# cyw20829 register map
Vendor: Infineon Technologies; Series: CYW20829; File version: 1.0
CPU: CM33 r0p1, little endian, MPU, no FPU, VTOR, 3 interrupt priority bits
Registers are 32-bit, read-write, reset 0x0 unless marked. A register's access mark holds for its fields unless they carry their own. Offsets are from the block's base; [hi:lo] are bit positions; lines under a group give offsets from that group; {n}, {i} and the like mark numbered series; 'fields as' and 'values as' point back to an identical list; <NAME> marks a mode.

## SMIF0 — Serial Memory Interface
Base 0x40890000
0x00 CTL reset 0x503400 — Control
  [31] ENABLED — IP enable: '0': Disabled. All non-retention registers are reset to their default value when the IP is disabled. When the IP is disabled, the XIP accesses produce AHB-Lite bus errors and AXI error responses. '1': Enabled. Notes: - Before disabling or resetting the IP, SW should ensure that the IP is NOT busy (STATUS.BUSY is '0'), otherwise illegal interface transfers may occur. - After CTL.ENABLED is set to 1 it takes up to 20 clk_if cycles until the memory interface registers are realeased from reset.
    0=DISABLED (N/A); 1=ENABLED (N/A)
  [25] CLOCK_IF_SEL — Specifies the clock source for 'clk_if'. Must be 0 (clk_hf) before entering DeepSleep; can be returned to 1 (clk_pll) afterwards. '0': clk_hf is used to create clk_if '1': clk_pll is used to create clk_if
  [24] BLOCK — Specifies what happens for MMIO interface read accesses to an empty RX data FIFO or to a full TX format/data FIFO. This field is not used for test controller accesses.
    0=BUS_ERROR (0': Generate an AHB-Lite bus error. This option is useful when SW decides to use polling on STATUS.TR_BUSY to determine if a interface transfer is no longer busy (transfer is completed). This option adds SW complexity, but limits the number of AHB-Lite wait states (and limits ISR latency).); 1=WAIT_STATES (1': Introduce wait states. This setting potentially locks up the AHB-Lite infrastructure and may increase the CPU interrupt latency.This option is useful when SW performs TX/RX data FIFO accesses immediately after a command is setup using the TX format FIFO. This option has low SW complexity, but may result in a significant number of AHB-Lite wait states (and may increase ISR latency). This can be particularly true if ARB_MODE=1 and an MMIO access must wait a potentially long time behind a XIP access.)
  [23:22] SELECT_HOLD_DELAY — Specifies the duration between last 'spi_clk_out' edge to 'spi_select_out[]' becomes high/'1'): '0': 0 memory interface clock cycles + min. duration (see below). '1': 1 memory interface clock cycle + min. duration (see below). '2': 2 memory interface clock cycles + min. duration (see below). '3': 3 memory interface clock cycles + min. duration (see below). In addition to the number of cycles selected here there is a min. duration of: - 1/2 memory interface clock cycle (= 1 clk_if cycles) for SDR timing (CLOCK_IF_TX_SEL = 0) - 1/4 memory interface clock cycle (= 1/2 clk_if cycle) for DDR timing (CLOCK_IF_TX_SEL = 1)
  [21:20] SELECT_SETUP_DELAY — Specifies the duration between 'spi_select_out[]' becomes low/'0') to 1st 'spi_clk_out' edge: '0': 0 memory interface clock cycles + min. duration (see below). '1': 1 memory interface clock cycle + min. duration (see below). '2': 2 memory interface clock cycles + min. duration (see below). '3': 3 memory interface clock cycles + min. duration (see below). In addition to the number of cycles selected here there is a min. duration of: - 1 memory interface clock cycle (= 2 clk_if cycle) for SDR timing (CLOCK_IF_TX_SEL = 0) - 1/4 memory interface clock cycle (= 1/2 clk_if cycle) for DDR timing (CLOCK_IF_TX_SEL = 1)
  [18:16] DESELECT_DELAY — Specifies the minimum duration of SPI deselection ('spi_select_out[]' is high/'1') in between SPI transfers: '0': 1 memory interface clock cycle. '1': 2 memory interface clock cycles. '2': 3 memory interface clock cycles. '3': 4 memory interface clock cycles. '4': 5 memory interface clock cycles. '5': 6 memory interface clock cycles. '6': 7 memory interface clock cycles. '7': 8 memory interface clock cycles. During SPI deselection, 'spi_select_out[]' are '1'/inactive, 'spi_data_out[]' are '1' and 'spi_clk_out' is '0'/inactive.
  [14:12] CLOCK_IF_RX_SEL
  [11:10] INT_CLOCK_CAPTURE_CYCLE
  [9] INT_CLOCK_DL_ENABLED — Data Learning Enable for internal RX clock based on Data Learning Pattern. Only applies when CLOCK_IF_RX_SEL = [4..5] for selecting the internal clock based capture scheme and when DELAY_TAP_ENABLED = 1. Must be set to 0 otherwise. '0': Disabled. The delay line tap selections specified in registers INT_CLOCK_DELAY_TAP_SEL0/1 are not modified by HW. '1': Enabled. The delay linle tap selections specified in registers INT_CLOCK_DELAY_TAP_SEL0/1 are modified by HW based on the data learning pattern. From all capture clock delay line taps producing a match between the expected data learning pattern in register DLP and the captured data learning pattern from the memory device the middle one is selected.
  [8] DELAY_TAP_ENABLED — Delay Line Tap Enable. '0': Disabled. The delay line tap selections specified in registers DELAY_TAP_SEL or INT_CLOCK_DELAY_TAP_SEL0/1 are not used. The read data is directly captured by the RX data FIFO capture clock as specified by CLOCK_IF_RX_SEL and INT_CLOCK_CAPTURE_CYCLE. '1': Enabled. The delay line tap selections specified in registers DELAY_TAP_SEL or INT_CLOCK_DELAY_TAP_SEL0/1 are used. If the output / feedback clock based capture scheme (CLOCK_IF_RX_SEL = [0..3]) or the RWDS based capture scheme (CLOCK_IF_RX_SEL = [6..7]) is selected then the register DELAY_TAP_SEL is used to select the capture clock. If the internal clock based capture scheme (CLOCK_IF_RX_SEL = [4..5] and INT_CLOCK_CAPTURE_PRESENT = 1) is selected then the registers INT_CLOCK_DELAY_TAP_SEL0/1 are used to select the capture clock per data bit line (read data is captured by the capture logic and afterwards transferred to the RX data FIFO).
  [7:5] DELAY_LINE_SEL — Specifies the delay line used for RX data capturing with - output / feedback clock based capturing (when CLOCK_IF_RX_SEL = [0..3] and DELAY_TAP_ENABLED = 1) - internal clock based capturing (when CLOCK_IF_RX_SEL = [4..5], INT_CLOCK_CAPTURE_PRESENT = 1 and DELAY_TAP_ENABLED = 1) - RWDS based capturing (when CLOCK_IF_RX_SEL = [6..7])
  [4] CLOCK_IF_TX_SEL — Specifies device interface transmitter clock options. '0': SDR. Memory interface clock 'spihb_clk_out' is divided (by 2) interface clock 'clk_if', memory interface data signals are driven by divided (by 2) interface clock 'clk_if' with different phase than 'spihb_clk_out'. Results in driving memory interface data signals at falling 'spihb_clk_out' edge. '1': DDR. Memory interface clock 'spihb_clk_out' is divided (by 2) inverted interface clock 'clk_if_inv', memory interface data signals are driven with interface clock 'clk_if'. Results in driving memory interface data signals 90 degrees before rising and falling 'spihb_clk_out' edge.
  [0] XIP_MODE — Mode of operation. Note: this field should only be changed when the IP is disabled or when STATUS.BUSY is '0' and SW should not be executing from the XIP interface or MMIO interface.
    0=MMIO_MODE ('0': MMIO mode. Individual MMIO accesses to TX and RX FIFOs are used to generate a sequence of SPI transfers. This mode of operation allows for large flexibility in terms of the SPI transfers that can be generated.); 1=ARB_MODE (''1': Arbitration mode. Arbitrates XIP vs. MMIO accesses such that any ongoing, pending, or 'merged' transactions on XIP always take priority over any MMIO accesses to the device. However, if an MMIO access is in process it cannot be interrupted until it completes (as defined by sending the 'last command' via TX_CMD_MMIO_FIFO_WR). If MMIO accesses are not happening at all, though, then the XIP accesses endure no extra arbitration latency.)
0x04 STATUS ro reset not defined
  [31] BUSY — AHB Cache, AXI interface, cryptography, XIP, device interface, MPC (if present) initialization, or any other key logic busy in the IP: '0': not busy '1': busy When BUSY is '0', the IP can be safely disabled without: - the potential loss of transient write data. - the potential risk of aborting an inflight SPI device interface transfer. - disrupting MPC (if present) initialization When BUSY is '0', the mode of operation (ARB_MODE or MMIO_MODE) can be safely changed.
0x44 TX_CMD_FIFO_STATUS ro — Transmitter command FIFO status
  [3:0] USED4 — Number of entries that are used in the TX command FIFO. Legal range: [0, 8].
0x48 TX_CMD_MMIO_FIFO_STATUS ro — Transmitter command MMIO FIFO status
  [3:0] USED4 — Number of entries that are used in the TX command MMIO FIFO. Legal range: [0, 8].
0x50 TX_CMD_MMIO_FIFO_WR wo — Transmitter command MMIO FIFO write
  [26:0] DATA27
0x80 TX_DATA_MMIO_FIFO_CTL — Transmitter data MMIO FIFO control
  [2:0] TX_TRIGGER_LEVEL — Determines when the TX data MMIO FIFO 'tr_tx_req' trigger is activated: - Trigger is active when TX_DATA_MMIO FIFO_STATUS.USED <= TRIGGER_LEVEL.
0x84 TX_DATA_FIFO_STATUS ro — Transmitter data FIFO status
  [3:0] USED4 — Number of entries that are used in the TX data FIFO. Legal range: [0, 8].
0x88 TX_DATA_MMIO_FIFO_STATUS ro — Transmitter data MMIO FIFO status
  [3:0] USED4 — Number of entries that are used in the TX data MMIO FIFO. Legal range: [0, 8].
0x90 TX_DATA_MMIO_FIFO_WR1 wo — Transmitter data MMIO FIFO write
  [7:0] DATA0 — TX data (written to TX data MMIO FIFO).
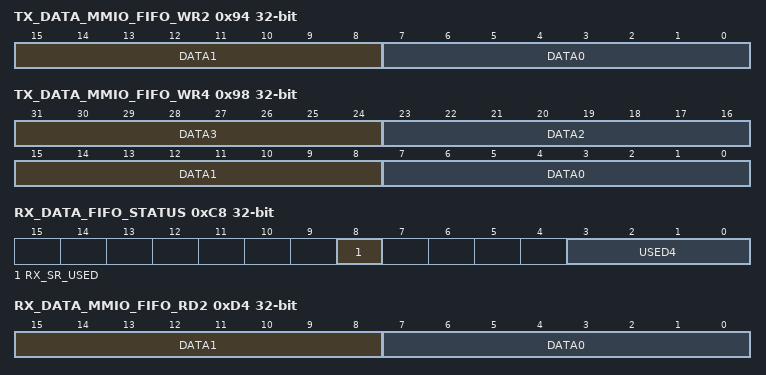
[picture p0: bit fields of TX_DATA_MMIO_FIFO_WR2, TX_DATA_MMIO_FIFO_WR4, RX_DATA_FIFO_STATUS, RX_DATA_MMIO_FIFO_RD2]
0x94 TX_DATA_MMIO_FIFO_WR2 wo — Transmitter data MMIO FIFO write
  [15:8] DATA1 — TX data (written to TX data MMIO FIFO, second byte).
  [7:0] DATA0 — TX data (written to TX data MMIO FIFO, first byte).
0x98 TX_DATA_MMIO_FIFO_WR4 wo — Transmitter data MMIO FIFO write
  [31:24] DATA3 — TX data (written to TX data MMIO FIFO, fourth byte).
  [23:16] DATA2 — TX data (written to TX data MMIO FIFO, third byte).
  [15:8] DATA1 — TX data (written to TX data MMIO FIFO, second byte).
  [7:0] DATA0 — TX data (written to TX data MMIO FIFO, first byte).
0x9C TX_DATA_MMIO_FIFO_WR1ODD wo — Transmitter data MMIO FIFO write
  [7:0] DATA0 — TX data (written to TX data MMIO FIFO).
0xC0 RX_DATA_MMIO_FIFO_CTL — Receiver data MMIO FIFO control
  [2:0] RX_TRIGGER_LEVEL — Determines when RX data FIFO 'tr_rx_req' trigger is activated: - Trigger is active when RX_DATA_MMIO_FIFO_STATUS.USED > TRIGGER_LEVEL.
0xC4 RX_DATA_MMIO_FIFO_STATUS ro — Receiver data MMIO FIFO status
  [3:0] USED4 — Number of entries that are used in the RX data MMIO FIFO. Legal range: [0, 8].
0xC8 RX_DATA_FIFO_STATUS ro — Receiver data FIFO status
  [8] RX_SR_USED — Data available in RX Shift Register, i.e. completely read from RX data FIFO.
  [3:0] USED4 — Number of entries that are used in the RX data FIFO. Legal range: [0, 8].
0xD0 RX_DATA_MMIO_FIFO_RD1 ro — Receiver data MMIO FIFO read
  [7:0] DATA0 — RX data (read from RX data FIFO).
0xD4 RX_DATA_MMIO_FIFO_RD2 ro — Receiver data MMIO FIFO read
  [15:8] DATA1 — RX data (read from RX data FIFO, second byte).
  [7:0] DATA0 — RX data (read from RX data FIFO, first byte).
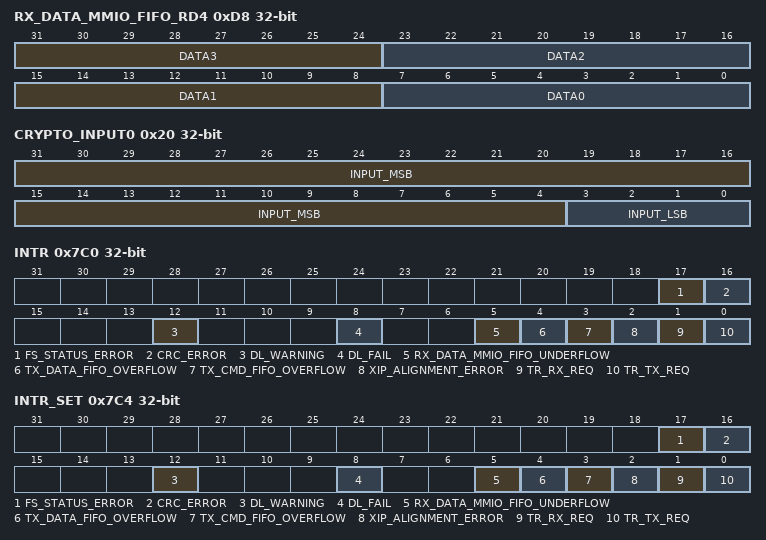
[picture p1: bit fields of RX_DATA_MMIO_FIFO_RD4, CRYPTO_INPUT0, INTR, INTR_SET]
0xD8 RX_DATA_MMIO_FIFO_RD4 ro — Receiver data MMIO FIFO read
  [31:24] DATA3 — RX data (read from RX data FIFO, fourth byte).
  [23:16] DATA2 — RX data (read from RX data FIFO, third byte).
  [15:8] DATA1 — RX data (read from RX data FIFO, second byte).
  [7:0] DATA0 — RX data (read from RX data FIFO, first byte).
0xE0 RX_DATA_MMIO_FIFO_RD1_SILENT ro — Receiver data MMIO FIFO silent read
  [7:0] DATA0 — RX data (read from RX data FIFO).
0x200 SMIF_CRYPTO group — Cryptography registers (one set for each key)
  0x00 CRYPTO_CMD — Cryptography command
    [0] START — SW sets this field to '1' to start an AES-128 forward block cipher operation (on CRYPTO_INPUT0-3). HW sets this field to '0' to indicate that the operation has completed. Once completed, the result of the operation can be read from CRYPTO_OUTPUT0, ..., CRYPTO_OUTPUT3. The operation takes roughly 13 clk_mem clock cycles. This register is only applicable for MMIO accesses and only in MMIO_MODE. XIP accesses are encrypted on-the-fly in ARB_MODE and thus do not use this register. Because XIP has exclusive access to the crypto engine in ARB_MODE, MMIO encryption is not available in that mode. As such if encryption is needed for MMIO accesses in ARB_MODE that encryption must be done by other means (i.e., chip level crypto).
  0x04 CRYPTO_ADDR — Cryptography base address
    [31:8] ADDR — Only applies to XIP accesses. Specifies the base address of the memory region that will have cryptography applied on XIP accesses with a unique key. If this region overlaps with another key's region, the lower numbered key is used (i.e., crypto key 0 has the highest priority). If the region is 2^m Bytes, ADDR MUST be a multiple of 2^m. The most significant bit fields are constants and set based on the SMIF_XIP_ADDR parameter. The most significant bits are identified on the SMIF_XIP_MASK parameter. E.g., if SMIF_XIP_MASK is 0xff00:0000 (16 MB XIP memory region), ADDR[31:24] = SMIF_XIP_ADDR[31:24]. Note that in order for cryptogrpahy to be applied the DEVICE.CTL.CRYPTO_EN must be set to 1 as well for any devices that share this region.
  0x08 CRYPTO_MASK — Cryptography mask
    [31:8] MASK — Only applies to XIP accesses. Specifies the size of the memory region whose base address is determined by CRYPTO_ADDR. All '1' bits are used to compare the incoming transfer request address A[31:0] with the address as specified in CRYPTO_ADDR.ADDR: Address A is in the cryptography region when (A[31:8] & MASK[31:8]) == CRYPTO_ADDR.ADDR[31:8]. The most significant bit fields are constants and set to'1'. The most significant bits are identified on the SMIF_XIP_MASK parameter. E.g., if SMIF_XIP_MASK is 0xff00:0000 (16 MB XIP memory region), MASK[31:24] = 0xff.
  0x0C CRYPTO_SUBREGION — Cryptography subregion disable
    [7:0] SUBREGION_DISABLE — Only applies to XIP accesses. The cryptography region for this key as determined by CRYPTO_ADDR and CRYPTO_MASK is further divided into 8 equal subregions. e.g., if a 1 MB region is specified then the 8 subregions will be 128 KB. If SUBREGION_DISABLE=0 then cryptography will be performed on that subregion (assuming any associated DEVICE.CTL.CRYPTO_EN=1). Otherwise if SUBREGION_DISABLE=1 then cryptography is not applied. Note that setting all SUBREGION_DISABLE bits to 1 will effectively disable this key. The encryption decision and the associated key are locked in at the beginning of a memory access and will apply until the end of such atomic accesses. Therefore, it is the user's responsibility to ensure memory accesses do not span across (sub)regions that have different keys and/or cypto enabled/disabled differently across such (sub)regions.
  0x20 CRYPTO_INPUT0 reset not defined — Cryptography input 0
    [31:4] INPUT_MSB — Plaintext PT[31:4] = CRYPTO_INPUT0.INPUT_MSB.
    [3:0] INPUT_LSB — Plaintext PT[3:0] = CRYPTO_INPUT0.INPUT_LSB.
  {0x20+4j} CRYPTO_INPUT{j} reset not defined (j=1..3) — Cryptography input {j}
    [31:0] INPUT — Plaintext PT[{32j+31}:{32j}] = CRYPTO_INPUT{j}.INPUT[31:0].
  {0x40+4j} CRYPTO_KEY{j} wo reset not defined (j=0..3) — Cryptography key {j}
    [31:0] KEY — Four Bytes of the key KEY[{32j+31}:{32j}] = CRYPTO_KEY{j}.KEY[31:0].
  {0x60+4j} CRYPTO_OUTPUT{j} reset not defined (j=0..3) — Cryptography output {j}
    [31:0] OUTPUT — Four Bytes of the ciphertext CT[{32j+31}:{32j}] = CRYPTO_OUTPUT{j}.OUTPUT[31:0].
0x7C0 INTR — Interrupt register
  [17] FS_STATUS_ERROR — Functional Safety Status Error. A read transfer Functional Safety Status check failed (see definition in DEVICE_ver2.RD_CRC_CTL.STATUS_CHECK_MASK and DEVICE_ver2.RD_CRC_CTL.STATUS_CHECK_MASK_POL).
  [16] CRC_ERROR — CRC Error. A read transfer data CRC check failed.
  [12] DL_WARNING — Data Learning Warning (for at least one input data line less then DLP.DL_WARNING_LEVEL delay line taps resulted in a correct DLP capturing when CTL.INT_CLOCK_DL_ENABLED = 1). This interrupt will be suppressed, though, if DL_FAIL also occurs during the same DLP evaluation cycle.
  [8] DL_FAIL — Data Learning Failed (no DLP match found on at least one of the input data lines when CTL.INT_CLOCK_DL_ENABLED = 1).
  [5] RX_DATA_MMIO_FIFO_UNDERFLOW — Activated on an AHB-Lite read transfer from the RX data MMIO FIFO (RX_DATA_MMIO_FIFO_RD1, RX_DATA_MMIO_FIFO_RD2, RX_DATA_MMIO_FIFO_RD4) with not enough entries available. Only activated for NON test bus controller transfers.
  [4] TX_DATA_FIFO_OVERFLOW — Activated on an AHB-Lite write transfer to the TX data MMIO FIFO (TX_DATA_MMIO_FIFO_WR1, TX_DATA_MMIO_FIFO_WR2, TX_DATA_MMIO_FIFO_WR4, TX_DATA_MMIO_FIFO_WR1ODD) with not enough free entries available.
  [3] TX_CMD_FIFO_OVERFLOW — Activated on an AHB-Lite write transfer to the TX command MMIO FIFO (TX_CMD_MMIO_FIFO_WR) with not enough free entries available.
  [2] XIP_ALIGNMENT_ERROR — Activated on a XIP access, when: - a write transfer is requested and - Dual-Quad SPI mode (selected device's ADDR_CTL.DIV2 is '1') is selected or - Octal SPI DDR mode (selected device's DATA_CTL.DDR_MODE = '1' and DATA_CTL.WIDTH = '3') or Hyperbus mode (selected device's ADDR_CTL.SIZE3 = '7') is selected without memory write byte masking (selected device's WR_DUMMY_CTL.RWDS_EN = '0') and - the AHB-Lite / AXI bus transfer address is not a multiple of '2' or - the requested AHB-Lite / AXI bus transfer size is NOT a multiple of '2'. Additionally, it is activated on a XIP access when the selected memory device does not support write byte masking (WR_DUMMY_CTL.RWDS_EN=0) and an AXI transfer occurs with not all of the AXI write strobes ('wstrb') enabled according to the transfer size ('assize'). Note: In dual-quad SPI mode (ADDR_CTL.DIV is '1'), each memory device contributes a 4-bit nibble for read data or write data. Write accesses are only possible if the request address is a multiple of 2 and the number of requested Bytes is a multiple of 2. Octal SPI DDR mode or Hyperbus mode are 16-bit word based protocols, writing single bytes is only possible when write byte masking is supported (via RWDS). Read accesses are always possible by extending the transfer size and / or aligning the address as needed and discarding the non-relevant byte(s).
  [1] TR_RX_REQ — Activated when a RX data MMIO FIFO trigger 'tr_rx_req' is activated.
  [0] TR_TX_REQ — Activated when a TX data MMIO FIFO trigger 'tr_tx_req' is activated.
0x7C4 INTR_SET — Interrupt set register
  [17] FS_STATUS_ERROR — Write with '1' to set corresponding bit in interrupt request register.
  [16] CRC_ERROR — Write with '1' to set corresponding bit in interrupt request register.
  [12] DL_WARNING — Write with '1' to set corresponding bit in interrupt request register.
  [8] DL_FAIL — Write with '1' to set corresponding bit in interrupt request register.
  [5] RX_DATA_MMIO_FIFO_UNDERFLOW — Write with '1' to set corresponding bit in interrupt request register.
  [4] TX_DATA_FIFO_OVERFLOW — Write with '1' to set corresponding bit in interrupt request register.
  [3] TX_CMD_FIFO_OVERFLOW — Write with '1' to set corresponding bit in interrupt request register.
  [2] XIP_ALIGNMENT_ERROR — Write with '1' to set corresponding bit in interrupt request register.
  [1] TR_RX_REQ — Write with '1' to set corresponding bit in interrupt request register.
  [0] TR_TX_REQ — Write with '1' to set corresponding bit in interrupt request register.
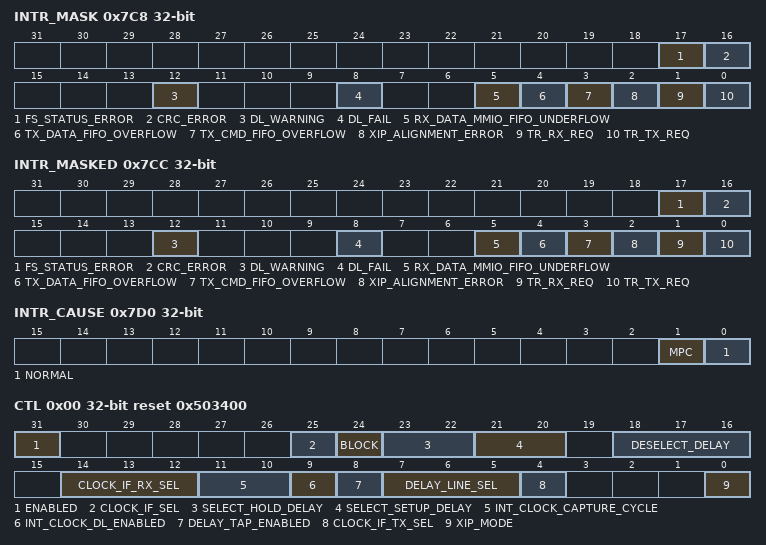
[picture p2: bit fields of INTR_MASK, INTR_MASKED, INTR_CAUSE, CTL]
0x7C8 INTR_MASK — Interrupt mask register
  [17] FS_STATUS_ERROR — Mask bit for corresponding bit in interrupt request register.
  [16] CRC_ERROR — Mask bit for corresponding bit in interrupt request register.
  [12] DL_WARNING — Mask bit for corresponding bit in interrupt request register.
  [8] DL_FAIL — Mask bit for corresponding bit in interrupt request register.
  [5] RX_DATA_MMIO_FIFO_UNDERFLOW — Mask bit for corresponding bit in interrupt request register.
  [4] TX_DATA_FIFO_OVERFLOW — Mask bit for corresponding bit in interrupt request register.
  [3] TX_CMD_FIFO_OVERFLOW — Mask bit for corresponding bit in interrupt request register.
  [2] XIP_ALIGNMENT_ERROR — Mask bit for corresponding bit in interrupt request register.
  [1] TR_RX_REQ — Mask bit for corresponding bit in interrupt request register.
  [0] TR_TX_REQ — Mask bit for corresponding bit in interrupt request register.
0x7CC INTR_MASKED ro — Interrupt masked register
  [17] FS_STATUS_ERROR — Logical and of corresponding request and mask bits.
  [16] CRC_ERROR — Logical and of corresponding request and mask bits.
  [12] DL_WARNING — Logical and of corresponding request and mask bits.
  [8] DL_FAIL — Logical and of corresponding request and mask bits.
  [5] RX_DATA_MMIO_FIFO_UNDERFLOW — Logical and of corresponding request and mask bits.
  [4] TX_DATA_FIFO_OVERFLOW — Logical and of corresponding request and mask bits.
  [3] TX_CMD_FIFO_OVERFLOW — Logical and of corresponding request and mask bits.
  [2] XIP_ALIGNMENT_ERROR — Logical and of corresponding request and mask bits.
  [1] TR_RX_REQ — Logical and of corresponding request and mask bits.
  [0] TR_TX_REQ — Logical and of corresponding request and mask bits.
0x7D0 INTR_CAUSE ro — Distinguishes normal vs. MPC interrupt
  [1] MPC — Reflects the state of interrupt_mpc (which is the OR of the elements in the MPC'S INTR_MASKED)
  [0] NORMAL — Reflects the state of interrupt_normal (which is the OR of the elements in the normal INTR_MASKED)
{0x800+0x80*i} DEVICE[{i}] (i=0..1) group — Device (only used for XIP acceses)
  0x00 CTL — Control
    [31] ENABLED — Device enable: '0': Disabled. '1': Enabled.
    [30] TOTAL_TIMEOUT_EN — Total transfer timeout enable. '0': Disabled. There is no limit for the total transfer time. The continuous transfer merge timeout for limiting the idle time of the memory interface still applies. '1': Enabled. The maximum total transfer time is limited by field TOTAL_TIMEOUT.
    [29:16] TOTAL_TIMEOUT — Total transfer timeout in clk_mem cycles. The counting of the total timout period is done in the XIP block using clk_mem cycles. It starts when the first command of a new (not merged) transaction is transferred to the TX command FIFO causing the interface logic to select the memory. After this period the memory device is deselected. This feature is needed for RAM devices requiring refresh cycles. The value needs to be derived from the RAMs maximum transaction length time (tCMS) minus the time of transferring 2x16byte data block (data granularity of the XIP ports is 16byte, 1 16byte block transfer outstanding, another available for merging). If the result in negative, MERGE_EN must be set to '0'. Example: RAM device tCMS = 4us, interface clock frequency = 100MHz: total transfer timeout is 4us - 2x16x10ns = 3680ns. With clk_mem frequency of 200MHz the TOTAL_TIMEOUT value is 3680/5 = 736. Note: In the unlikely case that the total transfer timeout is used (usually for RAM devices) while the page boundary crossing latency generation is enabled via RD_BOUND_CTL.PRESENT (usually for FLASH devices) the additional time needs to taken into account.
    [15] MERGE_EN — Continous transfer merge enable: '0': Disabled. No merging of transfers is done. Longest possible memory transfer is 16 Byte. '1': Enabled. Merging of continous transfers is done. This skips the overhead (command, address, mode, dummy cycles) for a continuous (linear sequential) transfer.
    [14:12] MERGE_TIMEOUT — Continuous transfer merge timeout in clk_mem cycles. This limits the standby time of the memory interface, i.e. the time the memory device is selected but no data is transferred. The counting of the merge timeout period is done in the XIP block using clk_mem cycles. It starts when the last TX or RX byte is transferred to or from the data FIFOs. After this period the memory device is deselected. A later transfer, even from a continuous address, starts with the overhead phases (command, address, mode, dummy cycles).
      0=_1_cycle (Timeout after 1 clk_mem cycle. That means transfers will only be merged if the continuous transfer request is already available when the previous transfer is finished.); 1=_16_cycles (Timeout after 2^4 = 16 clk_mem cycles. At a clk_mem frequency of 200MHz this means 80ns.); 2=_256_cycles (Timeout after 2^8 = 256 clk_mem cycles. At a clk_mem frequency of 200MHz this means ~1.3us.); 3=_4096_cycles (Timeout after 2^12 = 4096 clk_mem cycles. At a clk_mem frequency of 200MHz this means ~20us.); 4=_65536_cycles (Timeout after 2^16 = 65536 clk_mem cycles. At a clk_mem frequency of 200MHz this means ~330us.); 5=RSVD5 (N/A); 6=RSVD6 (N/A); 7=RSVD7 (N/A)
    [9:8] DATA_SEL — Specifies the connection of the IP's data lines (spi_data[0], ..., spi_data[7]) to the device's data lines (SI/IO0, SO/IO1, IO2, IO3, IO4, IO5, IO6, IO7): '0': spi_data[0] = IO0, spi_data[1] = IO1, ..., spi_data[7] = IO7. This value is allowed for single, dual, quad, dual quad and octal SPI modes. This value must be used for the first device in dual quad SPI mode. This value must be used for octal SPI mode. '1': spi_data[2] = IO0, spi_data[3] = IO1. This value is only allowed for single and dual SPI modes. '2': spi_data[4] = IO0, spi_data[5] = IO1, ..., spi_data[7] = IO3. This value is only allowed for single, dual, quad and dual quad SPI modes. In dual quad SPI mode, this value must be used for the second device. '3': spi_data[6] = IO0, spi_data[7] = IO1. This value is only allowed for single and dual SPI modes.
    [4] CRYPTO_EN — Cryptography on read/write accesses: '0': disabled. '1': enabled.
    [0] WR_EN — Write enable: '0': write transfers are not allowed to this device. An attempt to write to this device results in an AHB-Lite bus error. '1': write transfers are allowed to this device.
  0x08 ADDR reset not defined — Device region base address
    [31:8] ADDR — Specifies the base address of the device region. If the device region is 2^m Bytes, ADDR MUST be a multiple of 2^m. In dual quad SPI data transfer, the two devices should have the same ADDR and MASK register settings. The device control information (ADDR_CTL, RD_CMD_CTL, etc.) are provided by the MMIO control registers of the device with the lowest index. The most significant bit fields are constants and set based on the SMIF_XIP_ADDR parameter. The most significant bits are identified on the SMIF_XIP_MASK parameter. E.g., if SMIF_XIP_MASK is 0xff00:0000 (16 MB XIP memory region), ADDR[31:24] = SMIF_XIP_ADDR[31:24].
  0x0C MASK reset not defined — Device region mask
    [31:8] MASK — Specifies the size of the device region. All '1' bits are used to compare the incoming transfer request address A[31:0] with the address as specified in ADDR.ADDR: Address A is in the device when (A[31:8] & MASK[31:8]) == ADDR.ADDR[31:8]. The most significant bit fields are constants and set to'1'. The most significant bits are identified on the SMIF_XIP_MASK parameter. E.g., if SMIF_XIP_MASK is 0xff00:0000 (16 MB XIP memory region), MASK[31:24] = 0xff. Note: a transfer request that is not in any device region results in an AHB-Lite bus error.
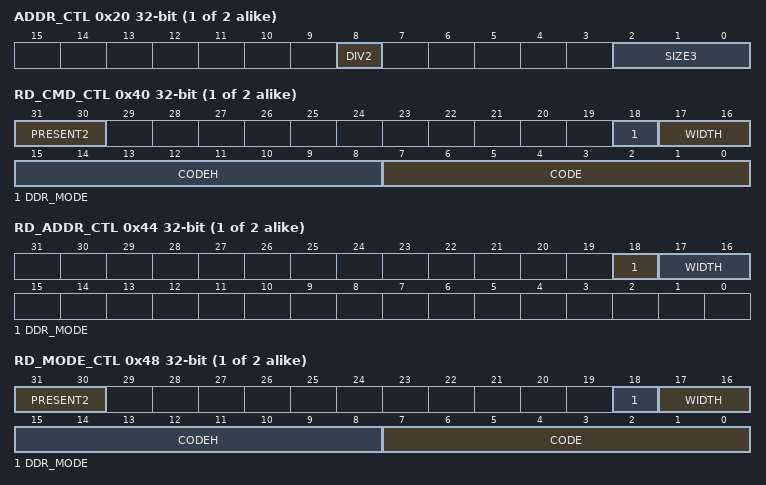
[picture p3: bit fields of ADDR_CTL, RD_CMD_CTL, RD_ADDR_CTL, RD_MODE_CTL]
  0x20 ADDR_CTL — Address control
    [8] DIV2 — Specifies if the AHB-Lite bus transfer address is divided by 2 or not: '0': No divide by 2. '1': Divide by 2. This functionality is used for read and write operation in XIP, dual quad SPI mode; i.e. this DIV2 must be set to '1' in dual quad SPI mode. If DIV2 is set to '1', the memory does not support write masking (WR_DUMMY_CTL.RWDS_EN = '0'), and in this configuration a write transfer is requested and the write transfer request address is NOT a multiple of 2 or the requested number of Bytes to be written is not a multiple of 2, the XIP_ALIGNMENT_ERROR interrupt cause is activated.
    [2:0] SIZE3
  0x2C DELAY_TAP_SEL reset 0x1 — RX Clock Delay Tap Select Register
    [7:0] SEL — Delay line tap selection in output / feedback clock based capture scheme (CLOCK_IF_RX_SEL = [0..3]) and RWDS capture scheme (CLOCK_IF_RX_SEL = [6..7]). This is used to shift the strobe signal into the data eye. Any 2 devices connected in a dual quad SPI arrangement must set this register equivalently. Note: DELAY_TAP_SEL must not be changed while STATUS.BUSY=1.
  0x30 RD_STATUS ro — Read status
    [7:0] FS_STATUS — Provides the Functional Safety Status Register of the memory received with the last read transfer.
  0x40 RD_CMD_CTL — Read command control
    [31:30] PRESENT2 — Presence of command field: '0': not present '1': present (1 Byte) '2': present (2 Byte for OPI) Note: For octal data transfer with DDR mode (WIDTH='3' and DDR_MODE='1') either the HB protocol needs to be selected (by ADDR_CTL.SIZE3='7') or this field needs to be set to PRESENT2='2'.
    [18] DDR_MODE — Mode of transfer rate: '0': SDR mode '1': DDR mode
    [17:16] WIDTH — Width of data transfer: '0': 1 bit/cycle (single data transfer). '1': 2 bits/cycle (dual data transfer). '2': 4 bits/cycle (quad data transfer). '3': 8 bits/cycle (octal data transfer).
    [15:8] CODEH — Command high byte code. This field specifies the most significant command byte, sent before the least significant command byte (CODE). It is only used when PRESENT2 = '2'.
    [7:0] CODE — Command byte code.
  0x44 RD_ADDR_CTL — Read address control
    [18] DDR_MODE — Mode of transfer rate.
    [17:16] WIDTH — Width of transfer.
  0x48 RD_MODE_CTL — Read mode control
    [31:30] PRESENT2 — Presence of mode field: '0': not present '1': present (1 Byte) '2': present (2 Byte for OPI) Note: For octal data transfer with DDR mode (WIDTH='3' and DDR_MODE='1') this field needs to be set to PRESENT2='2' to generate a mode field (or to PRESENT2='0').
    [18] DDR_MODE — Mode of transfer rate.
    [17:16] WIDTH — Width of transfer.
    [15:8] CODEH — Mode high byte code. This field specifies the most significant mode byte, sent before the least significant mode byte (CODE). It is only used when PRESENT2 = '2'.
    [7:0] CODE — Mode byte code. Note: If a mode field is present (PRESENT='1') for octal data transfer with DDR mode (WIDTH='3' and DDR_MODE='1') the CODE is sent twice.
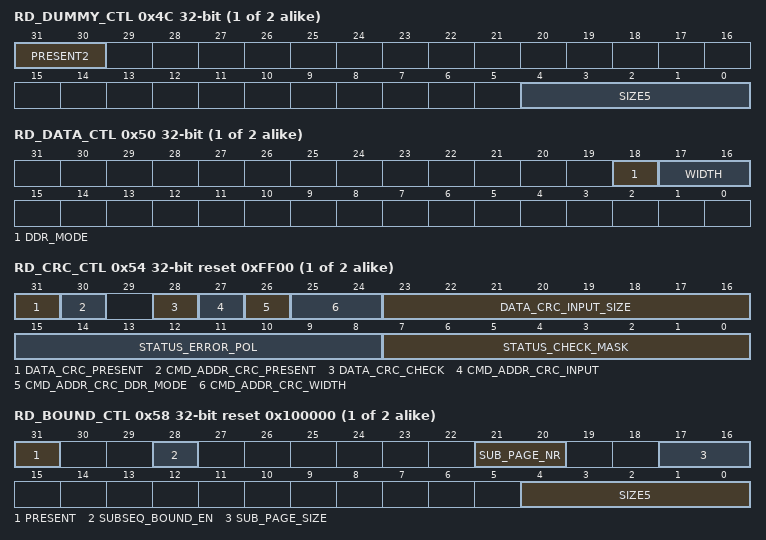
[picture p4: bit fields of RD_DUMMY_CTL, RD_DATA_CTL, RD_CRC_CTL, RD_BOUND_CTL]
  0x4C RD_DUMMY_CTL — Read dummy control
    [31:30] PRESENT2 — Presence of dummy cycles: '0': not present '1': present '2': present - Dummy cycles are doubled when RWDS refresh indicator is high during CA cycle. (HyperRAM variable latency mode) Notes: - If CLOCK_IF_TX_SEL = '0' for transmitting command, address and mode fields in SDR mode (driving data between falling edges of spihb_clk_out) and the memory is driving read data in DDR mode (based on memory type and transmitted command), then there must be at least 1 latency / dummy cycle specified (RD_DUMMY_CTL.PRESENT2 > 0') to prevent controller and memory driving data signals at the same time. The same is true for the theoretical (practically irrelevant case) of transmitting at least one of the command, address and mode fields in DDR mode but receiving data from the memory in SDR mode. - When using the RWDS / DQS based capturing scheme (CTL.CLK_IF_RX_SEL=[6,7]), then there is a minimum number of latency / dummy cycles required (RD_DUMMY_CTL.PRESENT2 > 0). For the Hyperbus protocol (DDR_CTL.SIZE3=7) at least 1 latency / dummy cycle has to be specified, for SPI with DQS capturing at least 2 latency / dummy cycles need to be selected (RD_DUMMY_CTL.SIZE5 > 0, exception see following note). - In case of falling edge RWDS / DQS capturing (CTL.CLOCK_IF_RX_SEL = '6') and SDR mode, SW should reduce the number of dummy cycles by 1 compared to the latency cycles required by the memory device. -DDR read commands need at least one dummy cycle -For Hyperbus, set RD DUMMY_CTL.SIZE5=initial latency cycles-2
    [4:0] SIZE5 — Number of dummy cycles (minus 1): '0': 1 cycles ... '31': 32 cycles. Note: this field specifies dummy cycles, not dummy Bytes!
  0x50 RD_DATA_CTL — Read data control
    fields as DEVICE[0].RD_ADDR_CTL
  0x54 RD_CRC_CTL reset 0xFF00 — Read Bus CRC control
    [31] DATA_CRC_PRESENT — Presence of data CRC field: '0': not present '1': present Note: Width and data transfer mode (SDR or DDR) of read data CRC fields are the same as for the associated read data fields, i.e. are specified by RD_DATA_CTL.WIDTH and RD_DATA_CTL.DDR_MODE.
    [30] CMD_ADDR_CRC_PRESENT — Presence of command / address CRC field: '0': not present '1': present Note: For octal data transfer with DDR mode (RD_CRC_CTL.WIDTH='3' and RD_CRC_CTL.DDR_MODE='1') the command / address CRC byte is sent twice, otherwise the command / address CRC byte is only sent once.
    [28] DATA_CRC_CHECK
    [27] CMD_ADDR_CRC_INPUT — Specifies which fields are included in the command / address CRC generation. '0': The command / address CRC field is generated over the address and (if present) mode fields only. '1': The command / address CRC field is generated over the command, address and (if present) mode fields.
    [26] CMD_ADDR_CRC_DDR_MODE — Mode of transfer rate of command / address CRC field.
    [25:24] CMD_ADDR_CRC_WIDTH — Width of command / address CRC field.
    [23:16] DATA_CRC_INPUT_SIZE — Number of input data bytes for CRC generation (minus 1), i.e. number of data bytes over which the data CRC field is generated (minus 1): '0': 1 byte ... '255': 256 bytes. Note: For octal data transfer with DDR mode (RD_DATA_CTL.WIDTH='3' and RD_DATA_CTL.DDR_MODE='1') the number of bytes for CRC generation must be even (i.e. DATA_CRC_INPUT_SIZE must be odd).
    [15:8] STATUS_ERROR_POL — Specifies the polarity of the Functional Safety Status field bits. There is 1 polarity bit for each Functional Safety Status bit. '0': The associated Functional Safety Status bit is active-low. '1': The associated Functional Safety Status bit is active-high.
    [7:0] STATUS_CHECK_MASK — Specifies which of the Functional Safety Status field bits are checked. There is 1 mask bit for each Functional Safety Status bit. '0': The associated Functional Safety Status bit is not checked. '1': The associated Functional Safety Status bit is checked. If the received Funciontal Safety Status bit = Functional Safety Status Error Polarity (STATUS_ERROR_POLARITY), then a Functional Safety Status error interrupt and a XIP bus error response is generated.
  0x58 RD_BOUND_CTL reset 0x100000 — Read boundary control
    [31] PRESENT — Presence of first page boundary latency cycles: '0': not present '1': present
    [28] SUBSEQ_BOUND_EN — Enable subsequent page boundary latency cycles. '0': Disabled. The page crossing latency cycles are only generated when crossing the first page boundary (i.e. the first time when the SUB_PAGE_NRth sub page boundary is crossed, e.g. with 2 sub pages per page when the 2nd sub page boundary is crossed). '1': Enabled. The page crossing latency cycles are generated when crossing the first and subsequent page boundaries (i.e. every time when a SUB_PAGE_NRth sub page boundary is crossed, e.g. with 2 sub pages per page when the 2nd, 4th, 6th, ... sub page boundary is crossed). Note: This only applies when the number of base latency cycles (SIZE5+1) is greater than the size of a page (base_latency > page_size). Must be set to 0 otherwise.
    [21:20] SUB_PAGE_NR — Specifies the number of sub pages per page. '0': 1 sub pages per page, i.e. page_size = sub_page_size '1': 2 sub pages per page, i.e. page_size = 2 x sub_page_size '2': 4 sub pages per page, i.e. page_size = 4 x sub_page_size '3': 8 sub pages per page, i.e. page_size = 8 x sub_page_size
    [17:16] SUB_PAGE_SIZE — Specifies the size of a memory sub page 'sub_page_size'. '0': sub_page_size = 8 words = 16 bytes (default). '1': sub_page_size = 16 words = 32 bytes. '2': sub_page_size = 32 words = 64 bytes. '3': sub_page_size = 64 words = 128 bytes.
    [4:0] SIZE5 — Number of base latency cycles (minus 1) used for calculating the number of fist page boundary crossing latency cycles: '0': base_latency = 1 cycles ... '31': base_latency = 32 cycles. The actual latency cycles when crossing the first page boundary depend on the start address of the transaction and is calculated as follows: if ((page_size - base_latency) < Start_Addr & (sub_page_size - 1)) { ((Start_Addr & (sub_page_size - 1)) - page_size + base_latency) } else { 0 }
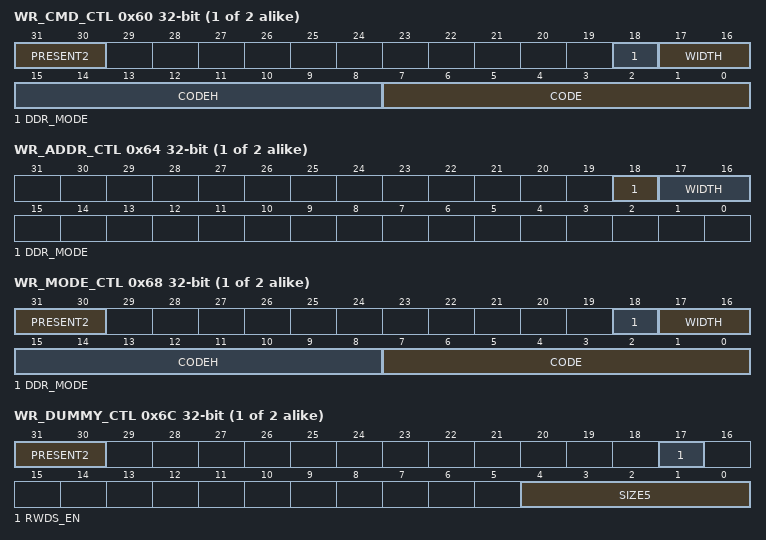
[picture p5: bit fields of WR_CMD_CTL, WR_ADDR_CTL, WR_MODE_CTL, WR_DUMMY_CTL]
  0x60 WR_CMD_CTL — Write command control
    [31:30] PRESENT2 — Presence of command field: '0': not present '1': present (1 Byte) '2': present (2 Byte for OPI) Note: For octal data transfer with DDR mode (WIDTH='3' and DDR_MODE='1') either the HB protocol needs to be selected (by ADDR_CTL.SIZE3='7') or this field needs to be set to PRESENT2='2'.
    [18] DDR_MODE — Mode of transfer rate.
    [17:16] WIDTH — Width of transfer.
    [15:8] CODEH — Command high byte code. This field specifies the most significant command byte, sent before the least significant command byte (CODE). It is only used when PRESENT2 = '2'.
    [7:0] CODE — Command byte code.
  0x64 WR_ADDR_CTL — Write address control
    fields as DEVICE[0].RD_ADDR_CTL
  0x68 WR_MODE_CTL — Write mode control
    [31:30] PRESENT2 — Presence of mode field: '0': not present '1': present (1 Byte) '2': present (2 Byte for OPI) Note: For octal data transfer with DDR mode (WIDTH='3' and DDR_MODE='1') this field needs to be set to PRESENT2='2' to generate a mode field (or to PRESENT2='0').
    [18] DDR_MODE — Mode of transfer rate.
    [17:16] WIDTH — Width of transfer.
    [15:8] CODEH — Mode high byte code. This field specifies the most significant mode byte, sent before the least significant mode byte (CODE). It is only used when PRESENT2 = '2'.
    [7:0] CODE — Mode byte code.
  0x6C WR_DUMMY_CTL — Write dummy control
    [31:30] PRESENT2 — Presence of dummy cycles: '0': not present '1': present '2': present - Dummy cycles are doubled when RWDS refresh indicator is high during CA cycle. (HyperRAM variable latency mode)
    [17] RWDS_EN — Read-Write-Data-Strobe Enable. Specifies whether the RWDS output signal should be driven starting in the last dummy cycle until DESELECT. This is needed for write transactions with byte masking via RWDS (e.g. Hyperbus). '0': do not drive RWDS output '1': drive RWDS output starting in last dummy cycle until DESELECT Note: this field is located in the WR_DUMMY_CTL register (and not in the WR_DATA_CTL register) since the RWDS signal needs to be driven already in the last dummy cycle.
    [4:0] SIZE5 — Number of dummy cycles (minus 1): '0': 1 cycles ... '31': 32 cycles.
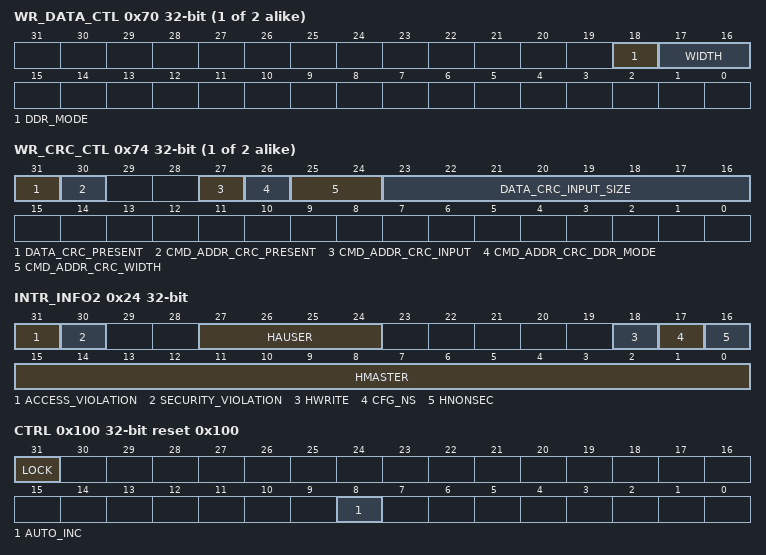
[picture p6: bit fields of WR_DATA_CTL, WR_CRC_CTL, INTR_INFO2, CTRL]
  0x70 WR_DATA_CTL — Write data control
    fields as DEVICE[0].RD_ADDR_CTL
  0x74 WR_CRC_CTL — Write Bus CRC control
    [31] DATA_CRC_PRESENT — Presence of data CRC field: '0': not present '1': present Note: Width and data transfer mode (SDR or DDR) of read data CRC fields are the same as for the associated read data fields, i.e. are specified by RD_DATA_CTL.WIDTH and RD_DATA_CTL.DDR_MODE. Note: For octal data transfer with DDR mode (RD_DATA_CTL.WIDTH='3' and RD_DATA_CTL.DDR_MODE='1') the data CRC byte is sent twice, otherwise the data CRC byte is only sent once.
    [30] CMD_ADDR_CRC_PRESENT — Presence of command / address CRC field: '0': not present '1': present Note: For octal data transfer with DDR mode (RD_CRC_CTL.WIDTH='3' and RD_CRC_CTL.DDR_MODE='1') the command / address CRC byte is sent twice, otherwise the command / address CRC byte is only sent once.
    [27] CMD_ADDR_CRC_INPUT — Specifies which fields are included in the command / address CRC generation. '0': The command / address CRC field is generated over the address and (if present) mode fields only. '1': The command / address CRC field is generated over the command, address and (if present) mode fields.
    [26] CMD_ADDR_CRC_DDR_MODE — Mode of transfer rate of command / address CRC field.
    [25:24] CMD_ADDR_CRC_WIDTH — Width of command / address CRC field.
    [23:16] DATA_CRC_INPUT_SIZE — Number of input data bytes for CRC generation (minus 1), i.e. number of data bytes over which the data CRC field is generated (minus 1): '0': 1 byte ... '255': 256 bytes. Note: For octal data transfer with DDR mode (WR_DATA_CTL.WIDTH='3' and WR_DATA_CTL.DDR_MODE='1') the number of bytes for CRC generation must be even (i.e. DATA_CRC_INPUT_SIZE must be odd).
0x1000 MPC group — MPC Memory Protection Controller registers
  0x00 CFG — Config register with error response, RegionID PPC_MPC_MAIN is the security owner PC. The error response configuration is located in CFG.RESPONSE, only one such configuration exists applying to all protection contexts in the system.
    [4] RESPONSE — Response Configuration for Security and PC violations 0: Read-Zero Write Ignore (RAZ/WI) 1: Bus Error
  0x10 INTR — Interrupt
    [0] VIOLATION — HW sets this field to '1', when a security violation is detected. SW writes '1' to this field to clear
  0x14 INTR_SET — Interrupt set
    [0] VIOLATION — SW write this field with '1' to set INTR register (a write of '0' has no effect).
  0x18 INTR_MASK — Interrupt mask
    [0] VIOLATION — Mask for corresponding field in INTR register.
  0x1C INTR_MASKED ro — Interrupt masked
    [0] VIOLATION — Logical AND of corresponding INTR and INTR_MASK fields.
  0x20 INTR_INFO1 ro — Infor about violation
    [31:0] VALUE — Full address of the access that caused violation
  0x24 INTR_INFO2 ro — Infor about violation
    [31] ACCESS_VIOLATION — This bit is set when a read or write transaction was done from a protection context that does not have access to this block of memory.
    [30] SECURITY_VIOLATION — This bit is set when a secure access was done to a non-secure block of memory, or a non-secure access was done to a secure block of memory.
    [27:24] HAUSER — The protection context from which the violating access was made (taken from the AHB5 HAUSER signal).
    [18] HWRITE — The R/W status from which the violating access was made.
    [17] CFG_NS — The secure/non-secure configuration of the block access attempt causing the violation.
    [16] HNONSEC — The security status of the access address causing the violation (taken from the AHB5 HNONSEC signal).
    [15:0] HMASTER — The master ID of the master that made the access causing the violation (taken from the AHB HMASTER signal)
  0x100 CTRL reset 0x100 — Control register with lock bit and auto-increment only (Separate CTRL for each PC depends on access_pc)
    [31] LOCK — Security lockdown for this protection context. Software can set this bit but not clear it once set. When set, write operations to BLK_LUT are not possible from this protection context. Setting LOCK also blocks writes to CTRL itself (for that PC copy). All writes are ignored.
    [8] AUTO_INC — Auto-increment BLK_IDX by 1 for this protection context as a side effect of each read/write access to BLK_LUT
  0x104 BLK_MAX ro — Max value of block-based index register
    [31:0] VALUE — Maximum value of block-based index register. The number and size blocks in an MPC is design time configurable and for embedded memories defaults to covering the entire memory using 4kB blocks; See product datasheet for details on protection of external memories.
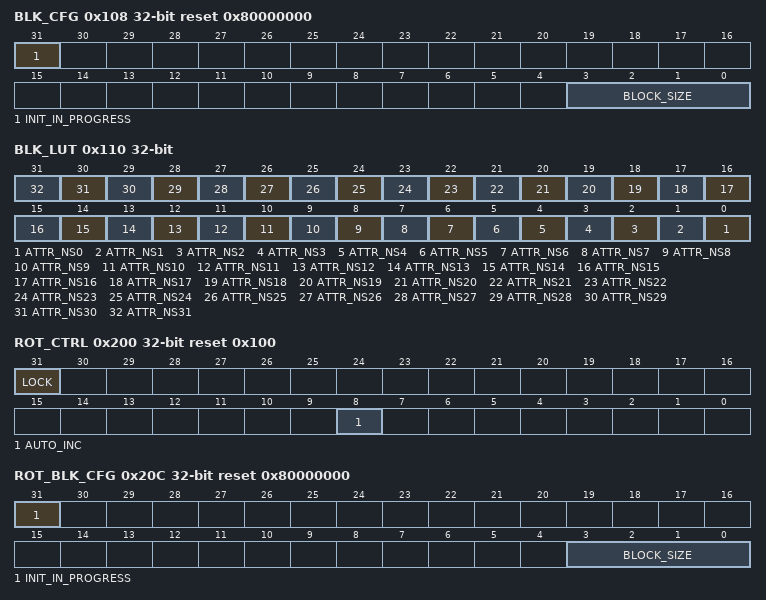
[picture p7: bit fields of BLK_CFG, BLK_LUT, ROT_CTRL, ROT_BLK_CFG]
  0x108 BLK_CFG ro reset 0x80000000 — Block size & initialization in progress
    [31] INIT_IN_PROGRESS — During initialization INIT_IN_PROGRESS is '1' and MMIO register accesses to BLK_LUT is blocked (BLK_IDX increment is also ignored). The block attributes are retained in DeepSleep (and obviously Active) power mode. Initialization is only required from a power mode in which the block attributes are not retained. E.g., initialization is required for a cold boot (after a Power-on-Reset). HW initializes the block attributes: the NS attributes are set to '0' (secure), the R attributes are set to '1' (read access allowed) and the W attributes are set to '1' (write access allowed). During initialization, the MPC supports memory accesses (memory accesses are NOT blocked) with the initialization block attribute values as mentioned above. This e.g. allows MPC initialization to proceed in parallel with boot program memory accesses (as opposed to serializing the two), improving device boot time. HW initializes the block attributes NS to 1 in case SECEXT = 0.
    [3:0] BLOCK_SIZE — Block size of individually protected blocks (0: 32B, 1: 64B, ... up to 15: 1MB) Block size= (1<<(BLOCK_SIZE+5)) The number and size blocks in an MPC is design time configurable and for embedded memories defaults to covering the entire memory using 4kB blocks; see product datasheet for details on protection of external memories.
  0x10C BLK_IDX — Index of 32-block group accessed through BLK_LUT (Separate IDX for each PC depending on access_pc)
    [31:0] VALUE — Index value for accessing block-based lookup table using BLK_LUT. Programming out of LUT range is an user error and it loops back to '0' once overflow occurs.
  0x110 BLK_LUT — NS status for 32 blocks at BLK_IDX with PC=<access_pc>
    [n] ATTR_NS{n} (n=0..31) — NS bit for block {n} based on BLK_IDX
  0x200 ROT_CTRL reset 0x100 — Control register with lock bit and auto-increment only
    [31] LOCK — Security lockdown for the root-of-trust configuration registers. Software can set this bit but not clear it once set. When set, write operations to ROT_BLK_LUT are not possible. Write is ignored.
    [8] AUTO_INC — Auto-increment BLK_IDX by 1 for each read/write of ROT_BLK_LUT
  0x204 ROT_CFG — Sets block-size to match memory size (external memory only)
    [3:0] BLOCK_SIZE — Block size of individually protected blocks (0: 32B, 1: 64B, ...up to 15:1 MB) Block size= (1<<(BLOCK_SIZE+5)) The number and size blocks in an MPC is design time configurable and for external memories defaults to covering the entire memory using 4kB blocks; see product datasheet for details on protection of external memories.
  0x208 ROT_BLK_MAX ro — Max value of block-based index register for ROT
    [31:0] VALUE — Maximum value of block-based index register. The number and size blocks in an MPC is design time configurable and for embedded memories defaults to covering the entire memory using 4kB blocks; see product datasheet for details on protection of external memories.
  0x20C ROT_BLK_CFG ro reset 0x80000000 — Same as BLK_CFG
    [31] INIT_IN_PROGRESS — During initialization INIT_IN_PROGRESS is '1' and MMIO register accesses to ROT_BLK_LUT is RAZWI. The block attributes are retained in DeepSleep (and obviously Active) power mode. Initialization is only required from a power mode in which the block attributes are not retained. E.g., initialization is required for a cold boot (after a Power-on-Reset). HW initializes the block attributes: the NS attributes are set to '0' (secure), the R attributes are set to '1' (read access allowed) and the W attributes are set to '1' (write access allowed). During initialization, the MPC supports memory accesses (memory accesses are NOT blocked) with the initialization block attribute values as mentioned above. This e.g. allows MPC initialization to proceed in parallel with boot program memory accesses (as opposed to serializing the two), improving device boot time. HW initializes the block attributes NS to 1 in case SECEXT = 0.
    [3:0] BLOCK_SIZE — Block size of individually protected blocks (0: 32B, 1: 64B, ...up to 15:1MB) Block size= (1<<(BLOCK_SIZE+5)) The number and size blocks in an MPC is design time configurable and for embedded memories defaults to covering the entire memory using 4kB blocks; see product datasheet for details on protection of external memories.
  0x210 ROT_BLK_IDX — Index of 8-block group accessed through ROT_BLK_LUT_*
    [31:0] VALUE — Index value for accessing block-based lookup table using ROT_BLK_LUT. Programming out of LUT range is an user error and it loops back to '0' once overflow occurs.
  0x214 ROT_BLK_PC — Protection context of 8-block group accesses through ROT_BLK_LUT
    [3:0] PC — Specify PC values for ROT_BLK_IDX and ROT_BLK_LUT
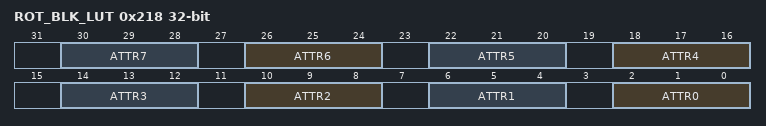
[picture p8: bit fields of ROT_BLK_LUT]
  0x218 ROT_BLK_LUT — (R,W,NS) bits for 8 blocks at ROT_BLK_IDX for PC=ROT_BKL_PC
    [4n+2:4n] ATTR{n} (n=0..7) — W/R/NS bits for block {n} indicated by ROT_BLK_IDX for ROT_BLK_PC PC
